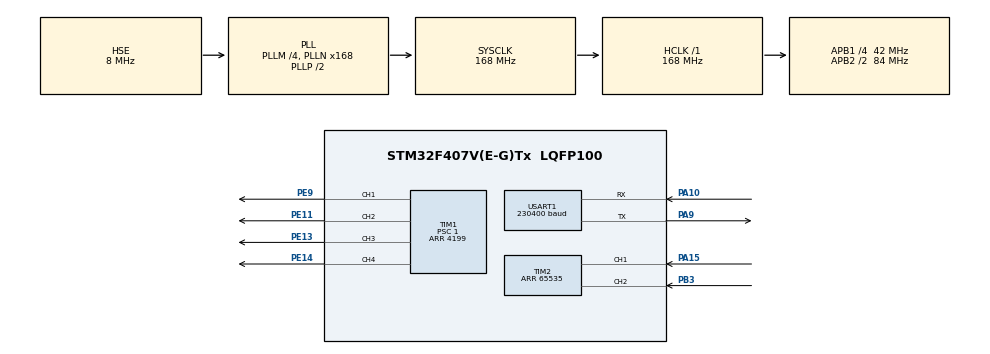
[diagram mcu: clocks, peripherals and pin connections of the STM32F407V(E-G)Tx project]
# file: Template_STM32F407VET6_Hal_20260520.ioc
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FREERTOS.Tasks01=defaultTask,24,128,StartDefaultTask,Default,NULL,Dynamic,NULL,NULL
Mcu.Family=STM32F4
Mcu.Name=STM32F407V(E-G)Tx
Mcu.Package=LQFP100
NVIC.PriorityGroup=NVIC_PRIORITYGROUP_4
NVIC.TIM3_IRQn=true\:15\:0\:false\:false\:true\:false\:false\:true\:true
NVIC.TimeBase=TIM3_IRQn
NVIC.TimeBaseIP=TIM3
NVIC.USART1_IRQn=true\:5\:0\:true\:false\:true\:true\:true\:true\:true
PA10.GPIO_PuPd=GPIO_NOPULL
PA10.Mode=Asynchronous
PA10.Signal=USART1_RX
PA13.Mode=Serial_Wire
PA13.Signal=SYS_JTMS-SWDIO
PA14.Mode=Serial_Wire
PA14.Signal=SYS_JTCK-SWCLK
PA15.Signal=S_TIM2_CH1_ETR
PA9.GPIO_PuPd=GPIO_NOPULL
PA9.Mode=Asynchronous
PA9.Signal=USART1_TX
PB3.Signal=S_TIM2_CH2
PE11.Signal=S_TIM1_CH2
PE13.Signal=S_TIM1_CH3
PE14.Signal=S_TIM1_CH4
PE9.Signal=S_TIM1_CH1
PH0-OSC_IN.Mode=HSE-External-Oscillator
PH0-OSC_IN.Signal=RCC_OSC_IN
PH1-OSC_OUT.Mode=HSE-External-Oscillator
PH1-OSC_OUT.Signal=RCC_OSC_OUT
ProjectManager.HeapSize=0x1200
ProjectManager.StackSize=0x800
ProjectManager.TargetToolchain=MDK-ARM V5.32
RCC.48MHZClocksFreq_Value=84000000
RCC.AHBFreq_Value=168000000
RCC.APB1CLKDivider=RCC_HCLK_DIV4
RCC.APB1Freq_Value=42000000
RCC.APB1TimFreq_Value=84000000
RCC.APB2CLKDivider=RCC_HCLK_DIV2
RCC.APB2Freq_Value=84000000
RCC.APB2TimFreq_Value=168000000
RCC.CortexFreq_Value=168000000
RCC.HCLKFreq_Value=168000000
RCC.HSE_VALUE=8000000
RCC.HSI_VALUE=16000000
RCC.LSE_VALUE=32768
RCC.PLLM=4
RCC.PLLN=168
RCC.PLLSourceVirtual=RCC_PLLSOURCE_HSE
RCC.SYSCLKFreq_VALUE=168000000
RCC.SYSCLKSource=RCC_SYSCLKSOURCE_PLLCLK
RCC.VCOOutputFreq_Value=336000000
SH.S_TIM1_CH1.0=TIM1_CH1,PWM Generation1 CH1
SH.S_TIM1_CH2.0=TIM1_CH2,PWM Generation2 CH2
SH.S_TIM1_CH3.0=TIM1_CH3,PWM Generation3 CH3
SH.S_TIM1_CH4.0=TIM1_CH4,PWM Generation4 CH4
SH.S_TIM2_CH1_ETR.0=TIM2_CH1,Encoder_Interface
SH.S_TIM2_CH2.0=TIM2_CH2,Encoder_Interface
TIM1.AutoReloadPreload=TIM_AUTORELOAD_PRELOAD_ENABLE
TIM1.Channel-PWM\ Generation1\ CH1=TIM_CHANNEL_1
TIM1.Channel-PWM\ Generation2\ CH2=TIM_CHANNEL_2
TIM1.Channel-PWM\ Generation3\ CH3=TIM_CHANNEL_3
TIM1.Channel-PWM\ Generation4\ CH4=TIM_CHANNEL_4
TIM1.Period=4199
TIM1.Prescaler=1
TIM1.Pulse-PWM\ Generation1\ CH1=0
TIM1.Pulse-PWM\ Generation2\ CH2=0
TIM1.Pulse-PWM\ Generation3\ CH3=0
TIM1.Pulse-PWM\ Generation4\ CH4=0
TIM2.AutoReloadPreload=TIM_AUTORELOAD_PRELOAD_ENABLE
TIM2.EncoderMode=TIM_ENCODERMODE_TI12
TIM2.IC1Filter=2
TIM2.IC2Filter=2
TIM2.Period=65535
USART1.BaudRate=230400
USART1.OverSampling=UART_OVERSAMPLING_8
USART1.VirtualMode=VM_ASYNC
VP_FREERTOS_VS_CMSIS_V2.Mode=CMSIS_V2
VP_SYS_VS_tim3.Mode=TIM3
VP_TIM1_VS_ClockSourceINT.Mode=Internal
board=custom

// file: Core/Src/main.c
/* USER CODE BEGIN Header */
/**
  ******************************************************************************
  * @file           : main.c
  * @brief          : Main program body
  ******************************************************************************
  * @attention
  *
  * Copyright (c) 2026 STMicroelectronics.
  * All rights reserved.
  *
  * This software is licensed under terms that can be found in the LICENSE file
  * in the root directory of this software component.
  * If no LICENSE file comes with this software, it is provided AS-IS.
  *
  ******************************************************************************
  */
/* USER CODE END Header */
#include "main.h"
#include "cmsis_os.h"
#include "tim.h"
#include "usart.h"
#include "gpio.h"

/* USER CODE BEGIN Includes */
#include "bsp_motor.h"
#include "test_motor.h"
/* USER CODE END Includes */

void SystemClock_Config(void);
void MX_FREERTOS_Init(void);

int main(void)
{

  /* MCU Configuration--------------------------------------------------------*/

  /* Reset of all peripherals, Initializes the Flash interface and the Systick. */
  HAL_Init();

  /* Configure the system clock */
  SystemClock_Config();

  /* Initialize all configured peripherals */
  MX_GPIO_Init();
  MX_TIM1_Init();
  MX_TIM2_Init();
  MX_USART1_UART_Init();
  /* USER CODE BEGIN 2 */
  BSP_Motor_Init(); /* 启动电机 PWM 输出 */

  /* 在这里直接调用裸机测试函数（内部有死循环，不会继续往下执行RTOS启动） */
  Test_Motor_Routine();
  /* USER CODE END 2 */

  /* Init scheduler */
  osKernelInitialize();  /* Call init function for freertos objects (in cmsis_os2.c) */
  MX_FREERTOS_Init();

  /* Start scheduler */
  osKernelStart();

  /* We should never get here as control is now taken by the scheduler */

  /* Infinite loop */
  while (1)
  {

  }
}

void SystemClock_Config(void)
{
  RCC_OscInitTypeDef RCC_OscInitStruct = {0};
  RCC_ClkInitTypeDef RCC_ClkInitStruct = {0};

  /** Configure the main internal regulator output voltage
  */
  __HAL_RCC_PWR_CLK_ENABLE();
  __HAL_PWR_VOLTAGESCALING_CONFIG(PWR_REGULATOR_VOLTAGE_SCALE1);

  /** Initializes the RCC Oscillators according to the specified parameters
  * in the RCC_OscInitTypeDef structure.
  */
  RCC_OscInitStruct.OscillatorType = RCC_OSCILLATORTYPE_HSE;
  RCC_OscInitStruct.HSEState = RCC_HSE_ON;
  RCC_OscInitStruct.PLL.PLLState = RCC_PLL_ON;
  RCC_OscInitStruct.PLL.PLLSource = RCC_PLLSOURCE_HSE;
  RCC_OscInitStruct.PLL.PLLM = 4;
  RCC_OscInitStruct.PLL.PLLN = 168;
  RCC_OscInitStruct.PLL.PLLP = RCC_PLLP_DIV2;
  RCC_OscInitStruct.PLL.PLLQ = 4;
  if (HAL_RCC_OscConfig(&RCC_OscInitStruct) != HAL_OK)
  {
    Error_Handler();
  }

  /** Initializes the CPU, AHB and APB buses clocks
  */
  RCC_ClkInitStruct.ClockType = RCC_CLOCKTYPE_HCLK|RCC_CLOCKTYPE_SYSCLK
                              |RCC_CLOCKTYPE_PCLK1|RCC_CLOCKTYPE_PCLK2;
  RCC_ClkInitStruct.SYSCLKSource = RCC_SYSCLKSOURCE_PLLCLK;
  RCC_ClkInitStruct.AHBCLKDivider = RCC_SYSCLK_DIV1;
  RCC_ClkInitStruct.APB1CLKDivider = RCC_HCLK_DIV4;
  RCC_ClkInitStruct.APB2CLKDivider = RCC_HCLK_DIV2;

  if (HAL_RCC_ClockConfig(&RCC_ClkInitStruct, FLASH_LATENCY_5) != HAL_OK)
  {
    Error_Handler();
  }
}

void HAL_TIM_PeriodElapsedCallback(TIM_HandleTypeDef *htim)
{
  if (htim->Instance == TIM3)
  {
    HAL_IncTick();
  }
}

void Error_Handler(void)
{
  __disable_irq();
  while (1)
  {
  }
}
